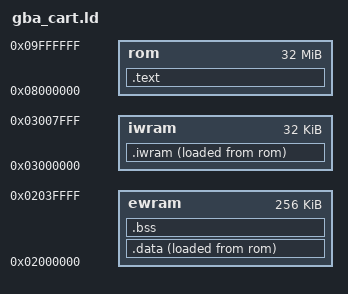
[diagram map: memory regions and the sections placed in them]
OUTPUT_FORMAT("elf32-littlearm", "elf32-littlearm", "elf32-littlearm")
OUTPUT_ARCH(arm)
ENTRY(_start)

MEMORY {
    rom   : ORIGIN = 0x08000000, LENGTH = 32M
    iwram : ORIGIN = 0x03000000, LENGTH = 32K
    ewram : ORIGIN = 0x02000000, LENGTH = 256K
}

__sp_irq = 0x03007FA0;
__sp_usr = 0x03007F00;

SECTIONS {
    .text : {
        KEEP(*(.text.startup))
        *(.text*)
        *(.rodata*)
        . = ALIGN(4);
    } > rom

    .iwram : {
        __iwram_start__ = .;
        *(.iwram*)
        . = ALIGN(4);
        __iwram_end__ = .;
    } > iwram AT > rom
    __iwram_lma = LOADADDR(.iwram);

    .data : {
        __data_start__ = .;
        *(.data*)
        . = ALIGN(4);
        __data_end__ = .;
    } > ewram AT > rom
    __data_lma = LOADADDR(.data);

    .bss (NOLOAD) : {
        __bss_start__ = .;
        *(.bss*)
        *(COMMON)
        . = ALIGN(4);
        __bss_end__ = .;
    } > ewram

    __end__ = .;
}
